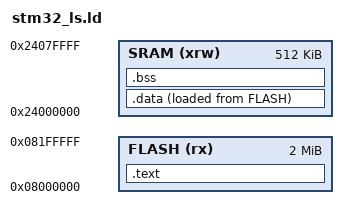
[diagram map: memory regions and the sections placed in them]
ENTRY(Reset_Handler)

MEMORY
{
  FLASH (rx)     : ORIGIN = 0x08000000, LENGTH = 2048K
  SRAM (xrw)     : ORIGIN = 0x24000000, LENGTH = 512K
}

SECTIONS
{
	.text : 
	{
		*(.isr-vector)
		*(.text)
		*(.text.*)
		*(.init)
		*(.fini)
		*(.rodata)
		*(.rodata.*)
		. = ALIGN(4);
		_etext = .;
	}> FLASH
	_la_data = LOADADDR(.data);
	.data :
	{
		_sdata = .;
		*(.data)
		*(.data.*)
		. = ALIGN(4);
		_edata = .;
	}> SRAM AT> FLASH

	.bss :
	{
		_sbss = .;
		__bss_start__ = _sbss;
		*(.bss)
		*(.bss.*)
		*(COMMON)
		. = ALIGN(4);
		_ebss = .;
		__bss_end__ = _ebss;
		. = ALIGN(4);
		end = .;
		__end__ = .;
	}> SRAM
}

